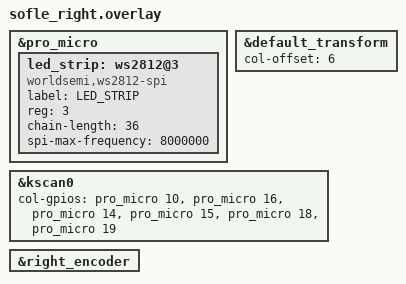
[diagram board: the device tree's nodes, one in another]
/*
 * Copyright (c) 2020 Ryan Cross
 *
 * SPDX-License-Identifier: MIT
 */

#include "sofle.dtsi"

// Configurazione strip WS2812 (underglow)
&pro_micro {
    led_strip: ws2812@3 {
        compatible = "worldsemi,ws2812-spi";
        label = "LED_STRIP";
        reg = <3>;
        chain-length = <36>;
        spi-max-frequency = <8000000>;
        status = "okay";
    };
};

&default_transform {
    col-offset = <6>;
};

&kscan0 {
    col-gpios
        = <&pro_micro 10 GPIO_ACTIVE_HIGH>
        , <&pro_micro 16 GPIO_ACTIVE_HIGH>
        , <&pro_micro 14 GPIO_ACTIVE_HIGH>
        , <&pro_micro 15 GPIO_ACTIVE_HIGH>
        , <&pro_micro 18 GPIO_ACTIVE_HIGH>
        , <&pro_micro 19 GPIO_ACTIVE_HIGH>
        ;
};

&right_encoder {
    status = "okay";
};
